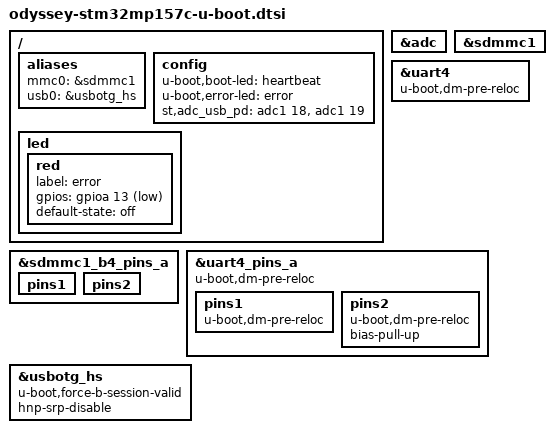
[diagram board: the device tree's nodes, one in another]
// SPDX-License-Identifier: GPL-2.0+ OR BSD-3-Clause
/*
 * Copyright (C) 2020 Marcin Sloniewski <marcin.sloniewski@gmail.com>
 */

 #include "odyssey-stm32mp157c-som-u-boot.dtsi"

/ {
	aliases {
		mmc0 = &sdmmc1;
		usb0 = &usbotg_hs;
	};
	config {
		u-boot,boot-led = "heartbeat";
		u-boot,error-led = "error";
		st,adc_usb_pd = <&adc1 18>, <&adc1 19>;
	};
	led {
		red {
			label = "error";
			gpios = <&gpioa 13 GPIO_ACTIVE_LOW>;
			default-state = "off";
			status = "okay";
		};
	};
};

&adc {
	status = "okay";
};

&sdmmc1 {
	u-boot,dm-spl;
};

&sdmmc1_b4_pins_a {
	u-boot,dm-spl;
	pins1 {
		u-boot,dm-spl;
	};
	pins2 {
		u-boot,dm-spl;
	};
};

&uart4 {
	u-boot,dm-pre-reloc;
};

&uart4_pins_a {
	u-boot,dm-pre-reloc;
	pins1 {
		u-boot,dm-pre-reloc;
	};
	pins2 {
		u-boot,dm-pre-reloc;
		/* pull-up on rx to avoid floating level */
		bias-pull-up;
	};
};

&usbotg_hs {
	u-boot,force-b-session-valid;
	hnp-srp-disable;
};
